# MK10D5 register map
File version: 1.6
Registers are 8-bit, read-write, reset 0x0 unless marked. A register's access mark holds for its fields unless they carry their own. Offsets are from the block's base; [hi:lo] are bit positions; {n}, {i} and the like mark numbered series.

## PTA — General Purpose Input/Output
Base 0x400FF000; register names take the prefix GPIOA_
0x00 PDOR 32-bit — Port Data Output Register
  [31:0] PDO — Port Data Output
    0=Logic level 0 is driven on pin provided pin is configured for General Purpose Output; 1=Logic level 1 is driven on pin provided pin is configured for General Purpose Output
0x04 PSOR 32-bit wo — Port Set Output Register
  [31:0] PTSO — Port Set Output
    0=Corresponding bit in PDORn does not change; 1=Corresponding bit in PDORn is set to logic one
0x08 PCOR 32-bit wo — Port Clear Output Register
  [31:0] PTCO — Port Clear Output
    0=Corresponding bit in PDORn does not change; 1=Corresponding bit in PDORn is set to logic zero
0x0C PTOR 32-bit wo — Port Toggle Output Register
  [31:0] PTTO — Port Toggle Output
    0=Corresponding bit in PDORn does not change; 1=Corresponding bit in PDORn is set to the inverse of its existing logic state
0x10 PDIR 32-bit ro — Port Data Input Register
  [31:0] PDI — Port Data Input
    0=Pin logic level is logic zero or is configured for use by digital function; 1=Pin logic level is logic one
0x14 PDDR 32-bit — Port Data Direction Register
  [31:0] PDD — Port data direction
    0=Pin is configured as general purpose input, if configured for the GPIO function; 1=Pin is configured for general purpose output, if configured for the GPIO function

## PTB — General Purpose Input/Output
Base 0x400FF040; register names take the prefix GPIOB_
Registers as PTA.

## PTC — General Purpose Input/Output
Base 0x400FF080; register names take the prefix GPIOC_
Registers as PTA; these are added or differ:
0x08 PCOR 32-bit wo — Port Clear Output Register
  [31:0] PTCO — Port Clear Output
    0=Corresponding bit in PDORn does not change; 1=Corresponding bit in PDORn is set to logic zero

## PTD — General Purpose Input/Output
Base 0x400FF0C0; register names take the prefix GPIOD_
Registers as PTA.

## PTE — General Purpose Input/Output
Base 0x400FF100; register names take the prefix GPIOE_
Registers as PTA.

## SysTick — System timer
Base 0xE000E010; register names take the prefix SYST_
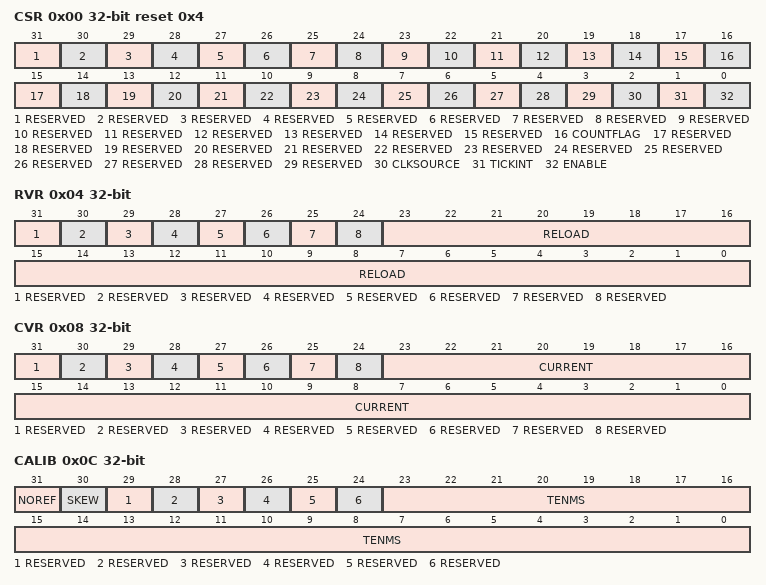
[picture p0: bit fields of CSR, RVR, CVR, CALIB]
0x00 CSR 32-bit access per field reset 0x4 — SysTick Control and Status Register
  [31] RESERVED ro
  [30] RESERVED ro
  [29] RESERVED ro
  [28] RESERVED ro
  [27] RESERVED ro
  [26] RESERVED ro
  [25] RESERVED ro
  [24] RESERVED ro
  [23] RESERVED ro
  [22] RESERVED ro
  [21] RESERVED ro
  [20] RESERVED ro
  [19] RESERVED ro
  [18] RESERVED ro
  [17] RESERVED ro
  [16] COUNTFLAG rw
  [15] RESERVED ro
  [14] RESERVED ro
  [13] RESERVED ro
  [12] RESERVED ro
  [11] RESERVED ro
  [10] RESERVED ro
  [9] RESERVED ro
  [8] RESERVED ro
  [7] RESERVED ro
  [6] RESERVED ro
  [5] RESERVED ro
  [4] RESERVED ro
  [3] RESERVED ro
  [2] CLKSOURCE rw
    0=external clock; 1=processor clock
  [1] TICKINT rw
    0=counting down to 0 does not assert the SysTick exception request; 1=counting down to 0 asserts the SysTick exception request
  [0] ENABLE rw
    0=counter disabled; 1=counter enabled
0x04 RVR 32-bit access per field — SysTick Reload Value Register
  [31] RESERVED ro
  [30] RESERVED ro
  [29] RESERVED ro
  [28] RESERVED ro
  [27] RESERVED ro
  [26] RESERVED ro
  [25] RESERVED ro
  [24] RESERVED ro
  [23:0] RELOAD rw — Value to load into the SysTick Current Value Register when the counter reaches 0
0x08 CVR 32-bit access per field — SysTick Current Value Register
  [31] RESERVED ro
  [30] RESERVED ro
  [29] RESERVED ro
  [28] RESERVED ro
  [27] RESERVED ro
  [26] RESERVED ro
  [25] RESERVED ro
  [24] RESERVED ro
  [23:0] CURRENT rw — Current value at the time the register is accessed
0x0C CALIB 32-bit ro — SysTick Calibration Value Register
  [31] NOREF
    0=The reference clock is provided; 1=The reference clock is not provided
  [30] SKEW
    0=10ms calibration value is exact; 1=10ms calibration value is inexact, because of the clock frequency
  [29] RESERVED
  [28] RESERVED
  [27] RESERVED
  [26] RESERVED
  [25] RESERVED
  [24] RESERVED
  [23:0] TENMS — Reload value to use for 10ms timing

## NVIC — Nested Vectored Interrupt Controller
Base 0xE000E100
{0x0+4i} NVICISER{i} 32-bit (i=0..3) — Interrupt Set Enable Register n
  [31:0] SETENA — Interrupt set enable bits
{0x80+4i} NVICICER{i} 32-bit (i=0..3) — Interrupt Clear Enable Register n
  [31:0] CLRENA — Interrupt clear-enable bits
{0x100+4i} NVICISPR{i} 32-bit (i=0..3) — Interrupt Set Pending Register n
  [31:0] SETPEND — Interrupt set-pending bits
{0x180+4i} NVICICPR{i} 32-bit (i=0..3) — Interrupt Clear Pending Register n
  [31:0] CLRPEND — Interrupt clear-pending bits
{0x200+4i} NVICIABR{i} 32-bit (i=0..3) — Interrupt Active bit Register n
  [31:0] ACTIVE — Interrupt active flags
{0x300+i} NVICIP{i} (i=0..105) — Interrupt Priority Register n
  [7:0] PRI{i} — Priority of interrupt {i}
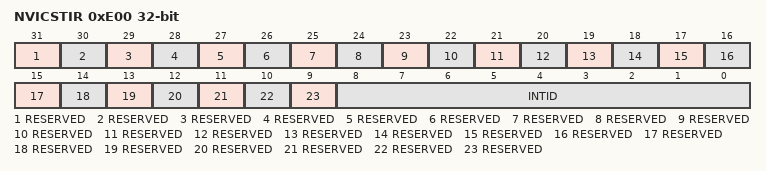
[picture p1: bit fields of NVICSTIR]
0xE00 NVICSTIR 32-bit — Software Trigger Interrupt Register
  [31] RESERVED
  [30] RESERVED
  [29] RESERVED
  [28] RESERVED
  [27] RESERVED
  [26] RESERVED
  [25] RESERVED
  [24] RESERVED
  [23] RESERVED
  [22] RESERVED
  [21] RESERVED
  [20] RESERVED
  [19] RESERVED
  [18] RESERVED
  [17] RESERVED
  [16] RESERVED
  [15] RESERVED
  [14] RESERVED
  [13] RESERVED
  [12] RESERVED
  [11] RESERVED
  [10] RESERVED
  [9] RESERVED
  [8:0] INTID — Interrupt ID of the interrupt to trigger, in the range 0-239. For example, a value of 0x03 specifies interrupt IRQ3.
